# R7FA2A2AD register map
Vendor: Renesas Electronics Corporation; Series: RA2A2; File version: 1.20.02
CPU: CM23 r1p0, little endian, MPU, no FPU, VTOR, 2 interrupt priority bits, 32 interrupts
Registers are 8-bit, read-write, reset 0x0 unless marked. A register's access mark holds for its fields unless they carry their own. Offsets are from the block's base; [hi:lo] are bit positions; {n}, {i} and the like mark numbered series.

## SDADC24_B — 24-Bit Sigma,Delta A/D Converter B
Base 0x4009C000
0x00 SDADCCR — Sigma,Delta A/D Clock Control Register
  [1:0] CK — Operating clock of the digital block
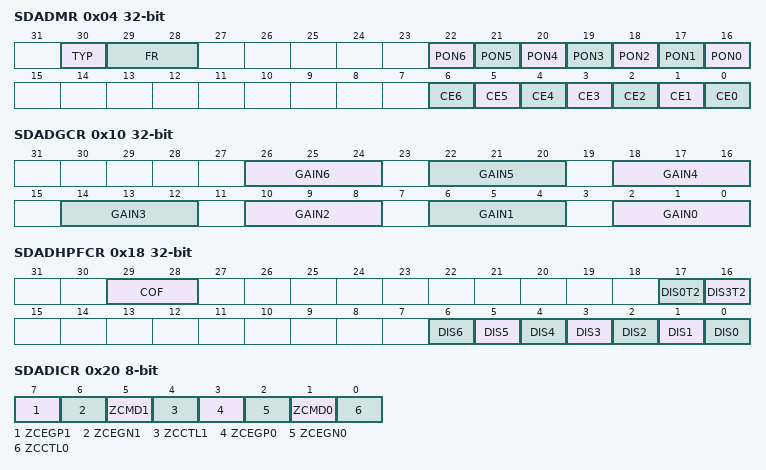
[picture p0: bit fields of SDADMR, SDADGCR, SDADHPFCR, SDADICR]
0x04 SDADMR 32-bit — Sigma,Delta A/D Mode Register
  [30] TYP — Resolution of A/D conversion result reading
  [29:28] FR — Sampling mode select
  [n+16] PON{n} (n=0..6) — Sigma,Delta A/D converter power,on control for channel n
  [n] CE{n} (n=0..6) — Sigma,Delta A/D converter operation enable for channel n
0x0C SDADRR — Sigma,Delta A/D Reset Register
  [0] RES — Sigma,Delta A/D converter reset
0x10 SDADGCR 32-bit — Sigma,Delta A/D Gain Control Register
  [4n+2:4n] GAIN{n} (n=0..6) — Preamplifier gain for channel {n}
0x18 SDADHPFCR 32-bit — Sigma,Delta A/D HPF Control Register
  [29:28] COF — Cut,off frequency of HPF (see )
  [17] DIS0T2 — HPF bypass for channel m Type 2 output
  [16] DIS3T2 — HPF bypass for channel m Type 2 output
  [n] DIS{n} (n=0..6) — HPF bypass for channel n Type 1 output
0x20 SDADICR — Sigma,Delta A/D Interrupt Control Register
  [7] ZCEGP1 — Rising edge detection enable for Zero,cross detection 1
  [6] ZCEGN1 — Falling edge detection enable for zero,cross detection 1
  [5] ZCMD1 — Interrupt output mode for zero,cross detection 1
  [4] ZCCTL1 — Detection channel for zero,cross detection 1
  [3] ZCEGP0 — Rising edge detection enable for zero,cross detection 0
  [2] ZCEGN0 — Falling edge detection enable for zero,cross detection 0
  [1] ZCMD0 — Interrupt output mode for zero,cross detection 0
  [0] ZCCTL0 — Detection channel for zero,cross detection 0
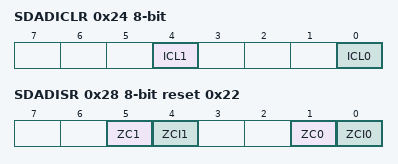
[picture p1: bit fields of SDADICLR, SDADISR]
0x24 SDADICLR — Sigma,Delta A/D Interrupt Clear Register
  [4] ICL1 wo — Zero,cross detection interrupt 1 clear
  [0] ICL0 wo — Zero,cross detection interrupt 0 clear
0x28 SDADISR reset 0x22 — Sigma,Delta A/D Interrupt Status Register
  [5] ZC1 ro — DF output status for Zero,cross detection 1
  [4] ZCI1 ro — Zero,cross detection interrupt status for zero,cross detection 1
  [1] ZC0 ro — DF output status for zero,cross detection 0
  [0] ZCI0 ro — Zero,cross detection interrupt status for zero,cross detection 0
{0x40+4i} SDADPHCR{i} (i=0..7) 16-bit — Sigma,Delta A/D Phase Control Register {i}
  [10:0] PH — Phase adjustment for channel n (n = 0 to 6)
{0x80+4i} SDADCR{i} (i=0..6) 32-bit ro — Sigma,Delta A/D Conversion Result Register {i} Type 1
  [31:0] SDADCR — A/D conversion result for channel n Type 1
{0xA0+4i} SDADCR{i}T2 (i=0..3) 32-bit ro — Sigma,Delta A/D Conversion Result Register {i} Type 2
  [31:0] SDADCR — A/D conversion result for channel m Type 2
{0xC0+4i} SDADCRLPF{i} (i=0..6) 32-bit ro — Sigma,Delta A/D Conversion Result Register (LPF) {i} Type 1
  [31:0] SDADCR — A/D conversion result for channel n LPF output Type 1
{0xE0+4i} SDADCRLPF{i}T2 (i=0..3) 32-bit ro — Sigma,Delta A/D Conversion Result Register (LPF) {i} Type 2
  [31:0] SDADCR — A/D conversion result for channel m LPF output Type 2

## MACL — 32-bit Multiply,Accumulator
Base 0x400A0000
{0x0+8i} MULB{i} (i=0..23) 32-bit — Multiplication Data Register Bn
{0xC0+8i} MULRL{i} (i=0..23) 32-bit — Multiplication Result Register {i}
{0xC4+8i} MULRH{i} (i=0..23) 32-bit (alternate view of MULRL{i}) — Multiplication Result Register {i}
0x180 MUL32U 32-bit — Multiplication Data Register A
0x184 MUL32S 32-bit (alternate view of MUL32U) — Multiplication Data Register A
0x188 MAC32U 32-bit (alternate view of MUL32U) — Multiplication Data Register A
0x18C MAC32S 32-bit (alternate view of MUL32U) — Multiplication Data Register A
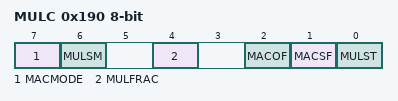
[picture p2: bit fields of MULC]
0x190 MULC — Multiplication Control Register
  [7] MACMODE — Operation Mode Selection
  [6] MULSM — Signedness Selection
  [4] MULFRAC — Fixed Point Mode Selection
  [2] MACOF ro — Multiply,accumulation Result (accumulation value) Overflow/Underflow Flag
  [1] MACSF ro — Multiply,accumulation Result (accumulation value) Sign Flag
  [0] MULST ro — Operation Processing Status Bit
0x194 MULRCLR 32-bit — Multiplication Result Clear Register
